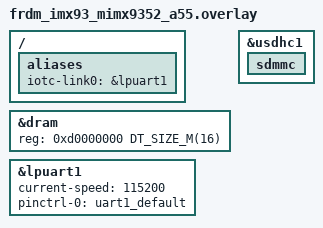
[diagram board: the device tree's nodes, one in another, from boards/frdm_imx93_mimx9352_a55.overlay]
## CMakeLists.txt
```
# gateway demo: IOTCONNECT gateway + eMMC store-and-forward on FRDM-i.MX93.
# Needs the iotc-zephyr-sdk module (-DZEPHYR_EXTRA_MODULES=<path>/iotc-zephyr-sdk).
cmake_minimum_required(VERSION 3.20.0)
find_package(Zephyr REQUIRED HINTS $ENV{ZEPHYR_BASE})
project(iotc_demo_gateway)

target_sources(app PRIVATE
  src/main.c
  src/uart_ingest.c
  src/spool.c
)

include(${CMAKE_CURRENT_SOURCE_DIR}/../../common/cmake/iotc_sdk_samples.cmake)

# quickstart_credentials.h: PUBLIC CA roots only (no device key). The
# per-device key/cert is provisioned on-chip (iotcprov provision).
target_include_directories(app PRIVATE
  ${IOTC_SDK_SAMPLES_DIR}/quickstart/src)
```

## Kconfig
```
# IOTCONNECT gateway demo configuration.

mainmenu "IOTCONNECT gateway demo"

menu "Gateway demo"

config GATEWAY_SPOOL_DISK_NAME
	string "Disk name for the store-and-forward spool"
	default "SD2"
	help
	  Zephyr disk-access name of the raw block device holding the spool
	  ring (on the FRDM-i.MX93, "SD2" = the on-SOM eMMC on uSDHC1, the
	  same disk the SDK's identity store uses).

config GATEWAY_SPOOL_SECTOR
	int "First sector of the spool ring"
	default 20100000
	help
	  Keep clear of the identity region (default sector 20,000,000 + 16)
	  and of anything else on the disk. The default sits ~10 GB into the
	  16 GB eMMC user area, which the SD-booted demo does not otherwise
	  use.

config GATEWAY_SPOOL_SLOTS
	int "Spool capacity in records (3 sectors / 1536 B each)"
	default 2048
	help
	  2048 slots = 3 MB = several hours of offline buffering at the demo
	  cadence (one gateway record per interval + one record per child
	  message).

config GATEWAY_SELF_TAG
	string "Gateway's own tag in the gateway template"
	default "gw"
	help
	  The "tg" stamped on the gateway's own telemetry records. Gateway
	  templates scope attributes by tag, and the platform binds values
	  only when the record's tg matches the attribute's tag.

config GATEWAY_LINK0_CHILD_ID
	string "Child device unique id for UART link 0"
	default "frdmmcxe31b01"
	help
	  Must match the child device's Unique ID on the platform. The
	  uart-telemetry-source demo announces itself as "<board>-01".

config GATEWAY_LINK0_TAG
	string "Gateway-template tag for UART link 0's child"
	default "uartsrc"
	help
	  The "tg" value sent with this child's records; must match the tag
	  the child template is attached under in the GATEWAY template.
	  Leave empty to omit "tg".

config GATEWAY_LINK1_CHILD_ID
	string "Child device unique id for UART link 1"
	default "frdmmcxw7201"

config GATEWAY_LINK1_TAG
	string "Gateway-template tag for UART link 1's child"
	default "uartsrc"

endmenu

source "Kconfig.zephyr"
```

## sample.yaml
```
sample:
  name: IOTCONNECT gateway demo
  description: >
    IOTCONNECT gateway with offline store-and-forward on the FRDM-i.MX93
    (Cortex-A55, Zephyr): ingests IOTCONNECT 2.1 JSON lines from
    connectivity-less MCUs over UART (demos/uart-telemetry-source), forwards
    them as child-device records over one MQTT/TLS uplink, and spools every
    record to a raw eMMC ring while offline -- reconnect backfills the
    timeline. Built on the iotc-zephyr-sdk.
tests:
  sample.iotconnect.gateway:
    harness: net
    platform_allow:
      - frdm_imx93/mimx9352/a55
    tags:
      - iotconnect
      - net
      - gateway
```

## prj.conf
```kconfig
# IOTCONNECT gateway demo -- vendor-neutral baseline.
# Provisioning model = quickstart (identity provisioned at runtime, on-chip
# keygen, only public CA roots compiled in). Board-specific networking,
# storage backend, and UART links live in boards/<board>.conf/.overlay.

# --- SDK + cloud -------------------------------------------------------------
CONFIG_IOTCONNECT=y
CONFIG_IOTCONNECT_DRA=y
CONFIG_IOTCONNECT_CT_AWS=y
CONFIG_IOTCONNECT_DRA_DISCOVERY_HOST="awsdiscovery.iotconnect.io"

# --- On-device provisioning (shell commands; storage backend per board) ------
# IDENTITY_NVS is the umbrella identity-store option; the backend (NVS vs
# TF-M PS vs raw disk) is picked by the board conf.
CONFIG_IOTCONNECT_IDENTITY_NVS=y
CONFIG_IOTCONNECT_ONDEVICE_KEYGEN=y
CONFIG_IOTCONNECT_SHELL=y
CONFIG_MBEDTLS_USER_CONFIG_FILE="iotc_mbedtls_config.h"
CONFIG_PSA_WANT_ALG_ECDSA=y
CONFIG_PSA_WANT_KEY_TYPE_ECC_KEY_PAIR_GENERATE=y
CONFIG_PSA_WANT_KEY_TYPE_ECC_KEY_PAIR_EXPORT=y
CONFIG_PSA_WANT_ECC_SECP_R1_256=y

# --- Shell (base64 cert/key + JSON paste need generous buffers) --------------
CONFIG_SHELL=y
CONFIG_SHELL_CMD_BUFF_SIZE=3072
CONFIG_SHELL_BACKEND_SERIAL_RX_RING_BUFFER_SIZE=4096
CONFIG_KERNEL_SHELL=y
CONFIG_REBOOT=y

# --- UART ingest links (interrupt-driven RX) ---------------------------------
CONFIG_SERIAL=y
CONFIG_UART_INTERRUPT_DRIVEN=y
CONFIG_RING_BUFFER=y

# --- Spool record integrity --------------------------------------------------
CONFIG_CRC=y

# --- Networking (native Zephyr IP stack) -------------------------------------
CONFIG_NETWORKING=y
CONFIG_NET_NATIVE=y
CONFIG_NET_IPV4=y
CONFIG_NET_IPV6=n
CONFIG_NET_TCP=y
CONFIG_NET_UDP=y
CONFIG_NET_SOCKETS=y
CONFIG_NET_SOCKETS_SOCKOPT_TLS=y
CONFIG_NET_SOCKETS_TLS_MAX_CONTEXTS=4
CONFIG_DNS_RESOLVER=y
CONFIG_NET_CONNECTION_MANAGER=y
CONFIG_NET_MGMT=y
CONFIG_NET_MGMT_EVENT=y
CONFIG_POSIX_API=y

# --- TLS / mbedTLS -----------------------------------------------------------
CONFIG_TLS_CREDENTIALS=y
CONFIG_MBEDTLS=y
CONFIG_MBEDTLS_ENABLE_HEAP=y
CONFIG_MBEDTLS_HEAP_SIZE=75000
CONFIG_MBEDTLS_SSL_MAX_CONTENT_LEN=16384
CONFIG_MBEDTLS_PEM_PARSE_C=y
CONFIG_MBEDTLS_SSL_SERVER_NAME_INDICATION=y
CONFIG_MBEDTLS_CIPHERSUITE_TLS_ECDHE_RSA_WITH_AES_128_GCM_SHA256=y
# discovery.iotconnect.io (production instances) only accepts TLS 1.2 CBC suites
CONFIG_MBEDTLS_CIPHERSUITE_TLS_ECDHE_RSA_WITH_AES_128_CBC_SHA256=y
CONFIG_MBEDTLS_CIPHERSUITE_TLS_ECDHE_ECDSA_WITH_AES_128_GCM_SHA256=y
CONFIG_ENTROPY_GENERATOR=y

# --- MQTT / HTTP / SNTP ------------------------------------------------------
CONFIG_MQTT_LIB=y
CONFIG_MQTT_LIB_TLS=y
CONFIG_MQTT_KEEPALIVE=30
CONFIG_HTTP_CLIENT=y
CONFIG_SNTP=y
CONFIG_POSIX_TIMERS=y

# Child records + gateway vitals in one 2.1 message need TX headroom.
CONFIG_IOTCONNECT_MQTT_TX_BUF_SIZE=2048

# --- libc / heap / stacks ----------------------------------------------------
CONFIG_PICOLIBC_IO_FLOAT=y
CONFIG_MAIN_STACK_SIZE=12288
CONFIG_SHELL_STACK_SIZE=8192
CONFIG_HEAP_MEM_POOL_SIZE=65536
CONFIG_IOTCONNECT_THREAD_STACK_SIZE=6144

# --- Logging -----------------------------------------------------------------
CONFIG_LOG=y
CONFIG_IOTCONNECT_LOG_LEVEL_INF=y

# Device vitals: append a "sys" object (CPU/heap/temp/uptime/reset) to telemetry.
CONFIG_IOTCONNECT_DEVICE_VITALS=y
```

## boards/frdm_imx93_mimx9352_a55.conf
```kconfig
# FRDM-IMX93 Cortex-A55 board config for the gateway demo.
#
# Same Zephyr-on-A55 platform recipe as the quickstart (Ethernet bearer,
# raw-eMMC identity store -- this target has no NOR flash and no NVS), plus
# the demo's own eMMC spool region and the lpuart1 ingest link enabled in
# boards/frdm_imx93_mimx9352_a55.overlay.
#
# Board target: frdm_imx93/mimx9352/a55  (needs the aarch64-zephyr-elf
# toolchain; build with USE_NXP_SPSDK_IMAGE=y for the bootable flash.bin).

# --- Bearer: native Ethernet (i.MX93 ENET, RGMII, Motorcomm YT8521 PHY) -----
CONFIG_NET_L2_ETHERNET=y
CONFIG_ETH_NXP_ENET=y
CONFIG_MDIO=y
CONFIG_NET_DHCPV4=y
CONFIG_NET_CONFIG_AUTO_INIT=y
CONFIG_NET_CONFIG_NEED_IPV4=y
CONFIG_NET_CONFIG_SETTINGS=y
CONFIG_NET_PKT_RX_COUNT=16
CONFIG_NET_PKT_TX_COUNT=16
CONFIG_NET_BUF_RX_COUNT=32
CONFIG_NET_BUF_TX_COUNT=32
CONFIG_NET_CONTEXT_RCVTIMEO=y
CONFIG_MBEDTLS_HEAP_SIZE=60000

# --- Identity persistence: raw eMMC sector region (no NOR flash here) --------
CONFIG_SETTINGS=n
CONFIG_SETTINGS_NVS=n
CONFIG_NVS=n
CONFIG_FLASH=n
CONFIG_FLASH_MAP=n
CONFIG_IOTCONNECT_IDENTITY_DISK=y
CONFIG_IOTCONNECT_IDENTITY_DISK_NAME="SD2"
CONFIG_IOTCONNECT_IDENTITY_DISK_SECTOR=20000000

# --- eMMC block access: identity store + the demo's spool ring ---------------
# (spool region: CONFIG_GATEWAY_SPOOL_* defaults -- sector 20,100,000, 3 MB)
CONFIG_DISK_ACCESS=y
CONFIG_DISK_DRIVER_MMC=y
CONFIG_MMC_STACK=y
CONFIG_SDHC=y
```

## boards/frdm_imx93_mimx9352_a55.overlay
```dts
/*
 * FRDM-IMX93 Cortex-A55 gateway overlay.
 *   - Extend the Zephyr DRAM window (the 1 MB board default is too small for
 *     arm64 + net + TLS + keygen). Must fit the DDR region your BSP reserves.
 *   - Enable usdhc1 (the on-SOM eMMC, disk "SD2"): the SDK's identity store
 *     and the demo's store-and-forward spool ring both live there. The ROM
 *     boots from the uSDHC2 SD slot; per the board doc Zephyr storage must
 *     use a DIFFERENT controller, and the eMMC qualifies.
 *   - Enable lpuart1 as UART ingest link 0 (alias iotc-link0): wire a
 *     uart-telemetry-source board's TX to UART1 RXD = 40-pin header P11
 *     pin 7 (net GPIO_IO04; GND on pin 9), 115200 8N1. lpuart2 stays the
 *     console/shell. UART1 doubles as the A55 debug port through the
 *     CH342F bridge, so the second debug COM port can emulate a source
 *     (tools/emulate_source.py) -- but not while a real TX is wired.
 */

/ {
	aliases {
		iotc-link0 = &lpuart1;
	};
};

&dram {
	reg = <0xd0000000 DT_SIZE_M(16)>;
};

&usdhc1 {
	status = "okay";

	sdmmc {
		status = "okay";
	};
};

&lpuart1 {
	status = "okay";
	current-speed = <115200>;
	pinctrl-0 = <&uart1_default>;
	pinctrl-names = "default";
};
```

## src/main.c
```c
/*
 * Copyright (c) 2026 Avnet, Inc.
 * SPDX-License-Identifier: MIT
 *
 * gateway demo -- an IOTCONNECT gateway with offline store-and-forward, on
 * the NXP FRDM-i.MX93 (Cortex-A55) running Zephyr.
 *
 * Completes the repo's "telemetry source" arc: connectivity-less MCUs running
 * demos/uart-telemetry-source (FRDM-MCXE31B, FRDM-MCXW72) print IOTCONNECT
 * 2.1 JSON lines on a UART; this gateway ingests those lines, wraps each one
 * as a CHILD-DEVICE record ("id" + "tg" per the 2.1 gateway schema), adds its
 * own gateway telemetry + vitals, and publishes everything over one MQTT/TLS
 * connection.
 *
 * Resilience is the headline: when the uplink drops (pull the Ethernet
 * cable), every record -- gateway and children -- is spooled to a raw-sector
 * ring on the on-SOM eMMC with its original timestamp embedded. On reconnect
 * the spool drains oldest-first and the platform backfills the timeline.
 * Nothing is lost; the dashboard shows a gap-free history plus honest
 * spool/drop counters.
 *
 * Cloud commands: interval <s>, spool-info, spool-wipe, links, reboot.
 *
 * Child devices are created on the platform under this gateway device; each
 * UART link maps to one child (unique id + template tag) via Kconfig:
 *   CONFIG_GATEWAY_LINK0_CHILD_ID / CONFIG_GATEWAY_LINK0_TAG   (and LINK1).
 */

#include <stdbool.h>
#include <stddef.h>
#include <stdint.h>
#include <stdio.h>
#include <stdlib.h>
#include <string.h>
#include <ctype.h>

#include <zephyr/kernel.h>
#include <zephyr/logging/log.h>
#include <zephyr/sys/printk.h>
#include <zephyr/sys/reboot.h>
#include <zephyr/net/net_if.h>
#include <zephyr/net/net_mgmt.h>
#include <zephyr/net/net_event.h>
#include <zephyr/net/conn_mgr_monitor.h>

#include <cJSON.h>

#include "iotconnect.h"
#include "iotcl.h"
#include "iotcl_telemetry.h"
#include "iotcl_util.h"
#include "iotcl_c2d.h"
#include "iotc_time.h"
#include "iotc_mqtt_client.h"      /* raw publish for child/spooled records */
#include "iotconnect_identity.h"
#if defined(CONFIG_IOTCONNECT_DEVICE_VITALS)
#include "iotconnect_vitals.h"
#endif
#include "quickstart_credentials.h" /* PUBLIC CA roots only (no device key) */

#include "uart_ingest.h"
#include "spool.h"

LOG_MODULE_REGISTER(gateway, LOG_LEVEL_INF);

#define RECONNECT_PERIOD_SEC 20
#define DRAIN_PER_TICK 4
#define ISO_TS_LEN 32

static volatile int publish_interval_sec = 10;
static bool spool_ok;
static uint32_t fwd_total;          /* child records forwarded (live) */

static const struct {
	const char *child_id;
	const char *tag;
} link_map[INGEST_MAX_LINKS] = {
	{ CONFIG_GATEWAY_LINK0_CHILD_ID, CONFIG_GATEWAY_LINK0_TAG },
	{ CONFIG_GATEWAY_LINK1_CHILD_ID, CONFIG_GATEWAY_LINK1_TAG },
};

static void print_guide(const char *reason)
{
	printk("\n");
	printk("========================================================\n");
	printk("  IOTCONNECT GATEWAY -- device is not provisioned\n");
	printk("  (%s)\n", reason);
	printk("--------------------------------------------------------\n");
	printk("  1) Generate this device's identity ON the device:\n");
	printk("        iotcprov provision <your-duid>\n");
	printk("  2) In IOTCONNECT: import the gateway template, Create\n");
	printk("     Device (Self-Signed, GATEWAY) on it, and paste the\n");
	printk("     certificate printed above. Create the child devices\n");
	printk("     under it (see README).\n");
	printk("  3) Paste the downloaded iotcDeviceConfig.json:\n");
	printk("        iotc config\n");
	printk("        { ...paste the json block... }\n");
	printk("  4) Connect:  kernel reboot cold\n");
	printk("========================================================\n\n");
}

/* --- Publishing ------------------------------------------------------------ */

static void publish_raw(const char *json)
{
	IotclMqttConfig *mc = iotcl_mqtt_get_config();

	if (mc != NULL && mc->pub_rpt != NULL) {
		iotc_mqtt_client_publish(mc->pub_rpt, json);
	}
}

/*
 * Derive the platform child Unique ID from the source's self-reported board
 * name: strip separators (the platform allows only alphanumerics in child
 * IDs) and append "01", mirroring the source's "<board>-01" duid convention.
 * "frdm_mcxe31b" -> "frdmmcxe31b01". This makes the single wired link
 * board-agnostic: whichever source MCU is plugged in shows up as itself.
 */
static void child_id_from_board(const char *board, char *out, size_t out_size)
{
	size_t o = 0;

	for (; *board != '\0' && o < out_size - 3; board++) {
		char c = *board;

		if ((c >= 'a' && c <= 'z') || (c >= 'A' && c <= 'Z') ||
		    (c >= '0' && c <= '9')) {
			out[o++] = c;
		}
	}
	out[o++] = '0';
	out[o++] = '1';
	out[o] = '\0';
}

/*
 * Wrap one source line (a 2.1 message from uart-telemetry-source, shape
 * {"d":[{"d":{...}}]}, or any bare JSON object) as a gateway CHILD record:
 *   {"d":[{"id":"<child>","tg":"<tag>","dt":"<iso>","d":{...}}]}
 * The child id comes from the record's own "board" field when present
 * (see child_id_from_board), else the link's Kconfig default.
 * Returns a malloc'd string (cJSON_free() it) or NULL on parse failure.
 */
static char *build_child_record(int link, const char *src_json)
{
	cJSON *src = cJSON_Parse(src_json);
	cJSON *data = NULL;
	char *out = NULL;

	if (src == NULL) {
		return NULL;
	}

	/* Locate the inner data object; tolerate both envelope and bare form. */
	if (cJSON_IsObject(src)) {
		cJSON *arr = cJSON_GetObjectItem(src, "d");

		if (cJSON_IsArray(arr) && cJSON_GetArraySize(arr) > 0) {
			cJSON *item0 = cJSON_GetArrayItem(arr, 0);
			cJSON *inner = cJSON_GetObjectItem(item0, "d");

			if (cJSON_IsObject(inner)) {
				data = cJSON_DetachItemFromObject(item0, "d");
			}
		} else if (arr == NULL) {
			data = src; /* bare object: use it wholesale */
			src = NULL;
		}
	}
	if (data == NULL) {
		cJSON_Delete(src);
		return NULL;
	}

	cJSON *root = cJSON_CreateObject();
	cJSON *darr = cJSON_AddArrayToObject(root, "d");
	cJSON *item = cJSON_CreateObject();
	char ts[ISO_TS_LEN];
	char derived_id[48];
	const char *child_id = link_map[link].child_id;
	const char *board = cJSON_GetStringValue(
		cJSON_GetObjectItem(data, "board"));

	if (board != NULL && board[0] != '\0') {
		child_id_from_board(board, derived_id, sizeof(derived_id));
		child_id = derived_id;
	}
	cJSON_AddStringToObject(item, "id", child_id);
	if (link_map[link].tag[0] != '\0') {
		cJSON_AddStringToObject(item, "tg", link_map[link].tag);
	}
	if (iotcl_iso_timestamp_now(ts, sizeof(ts)) == 0) {
		cJSON_AddStringToObject(item, "dt", ts);
	}
	cJSON_AddItemToObject(item, "d", data);
	cJSON_AddItemToArray(darr, item);

	out = cJSON_PrintUnformatted(root);
	cJSON_Delete(root);
	cJSON_Delete(src);
	return out;
}

/* Gateway-own record: link health, spool state, vitals. Publishes live when
 * connected, otherwise serializes and spools with its timestamp. */
static void publish_or_spool_gateway(bool connected)
{
	struct spool_stats sp;
	struct ingest_stats st;
	char key[24];

	spool_get_stats(&sp);

	IotclMessageHandle msg = iotcl_telemetry_create();

	if (msg == NULL) {
		return;
	}
	iotcl_telemetry_set_number(msg, "gw.online", connected ? 1 : 0);
	iotcl_telemetry_set_number(msg, "gw.links", uart_ingest_link_count());
	iotcl_telemetry_set_number(msg, "gw.fwd_total", (double)fwd_total);
	/* iotc-c-lib telemetry paths allow at most ONE dot (hardware-observed
	 * rejection of deeper nesting), so spool/link fields are flattened. */
	iotcl_telemetry_set_number(msg, "gw.spool_count", (double)sp.count);
	iotcl_telemetry_set_number(msg, "gw.spool_pushed", (double)sp.pushed);
	iotcl_telemetry_set_number(msg, "gw.spool_drained", (double)sp.drained);
	iotcl_telemetry_set_number(msg, "gw.spool_drops", (double)sp.drops);

	for (int i = 0; i < INGEST_MAX_LINKS; i++) {
		uart_ingest_get_stats(i, &st);
		if (st.lines_ok == 0 && st.lines_dropped == 0) {
			continue;
		}
		snprintf(key, sizeof(key), "gw.link%d_rx", i);
		iotcl_telemetry_set_number(msg, key, (double)st.lines_ok);
		snprintf(key, sizeof(key), "gw.link%d_drop", i);
		iotcl_telemetry_set_number(msg, key, (double)st.lines_dropped);
		snprintf(key, sizeof(key), "gw.link%d_age_s", i);
		iotcl_telemetry_set_number(msg, key, st.last_seen_ms > 0 ?
			(double)(k_uptime_get() - st.last_seen_ms) / 1000.0 : -1.0);
	}
#if defined(CONFIG_IOTCONNECT_DEVICE_VITALS)
	iotc_vitals_append(msg);
#endif

	/*
	 * Gateway-template attributes are TAG-scoped; the platform binds a
	 * record's values only when the record carries the matching "tg"
	 * (hardware-observed: tg-less gateway records display all-null).
	 * iotcl has no tg support, so serialize, inject tg into the record,
	 * and publish/spool the raw JSON.
	 */
	char *json = iotcl_telemetry_create_serialized_string(msg, false);

	iotcl_telemetry_destroy(msg);
	if (json == NULL) {
		return;
	}

	cJSON *root = cJSON_Parse(json);

	iotcl_telemetry_destroy_serialized_string(json);
	if (root == NULL) {
		return;
	}

	cJSON *item0 = cJSON_GetArrayItem(cJSON_GetObjectItem(root, "d"), 0);

	if (item0 != NULL) {
		cJSON_AddStringToObject(item0, "tg", CONFIG_GATEWAY_SELF_TAG);
	}

	char *out = cJSON_PrintUnformatted(root);

	cJSON_Delete(root);
	if (out == NULL) {
		return;
	}
	if (connected) {
		publish_raw(out);
	} else if (spool_ok) {
		(void)spool_push(out);
	}
	cJSON_free(out);
}

/* --- C2D commands ----------------------------------------------------------- */

static bool tok_is(const char *tok, size_t len, const char *name)
{
	if (strlen(name) != len) {
		return false;
	}
	for (size_t i = 0; i < len; i++) {
		if (tolower((unsigned char)tok[i]) != (unsigned char)name[i]) {
			return false;
		}
	}
	return true;
}

static void on_command(IotclC2dEventData data)
{
	const char *cmd = iotcl_c2d_get_command(data);
	const char *ack = iotcl_c2d_get_ack_id(data);
	int status = IOTCL_C2D_EVT_CMD_FAILED;
	char note[128] = "unknown command";

	LOG_INF("C2D command: %.64s", cmd ? cmd : "(null)");
	if (cmd == NULL) {
		goto out;
	}
	while (*cmd == ' ') {
		cmd++;
	}
	const char *sp = strchr(cmd, ' ');
	size_t name_len = (sp != NULL) ? (size_t)(sp - cmd) : strlen(cmd);
	const char *arg = (sp != NULL) ? sp + 1 : NULL;

	while (arg != NULL && *arg == ' ') {
		arg++;
	}
	if (arg != NULL && *arg == '\0') {
		arg = NULL;
	}

	if (tok_is(cmd, name_len, "interval") && arg != NULL) {
		int v = atoi(arg);

		if (v >= 1 && v <= 3600) {
			publish_interval_sec = v;
			status = IOTCL_C2D_EVT_CMD_SUCCESS_WITH_ACK;
			snprintf(note, sizeof(note), "interval=%ds", v);
		} else {
			snprintf(note, sizeof(note), "interval out of range");
		}
	} else if (tok_is(cmd, name_len, "spool-info")) {
		struct spool_stats sp;

		spool_get_stats(&sp);
		snprintf(note, sizeof(note),
			 "%u/%u queued, pushed=%u drained=%u drops=%u%s",
			 (unsigned int)sp.count, (unsigned int)sp.capacity,
			 (unsigned int)sp.pushed, (unsigned int)sp.drained,
			 (unsigned int)sp.drops,
			 spool_ok ? "" : " (SPOOL OFFLINE)");
		status = IOTCL_C2D_EVT_CMD_SUCCESS_WITH_ACK;
	} else if (tok_is(cmd, name_len, "spool-wipe")) {
		if (spool_wipe() == 0) {
			status = IOTCL_C2D_EVT_CMD_SUCCESS_WITH_ACK;
			snprintf(note, sizeof(note), "spool wiped");
		} else {
			snprintf(note, sizeof(note), "spool wipe failed");
		}
	} else if (tok_is(cmd, name_len, "links")) {
		struct ingest_stats s0, s1;

		uart_ingest_get_stats(0, &s0);
		uart_ingest_get_stats(1, &s1);
		snprintf(note, sizeof(note),
			 "link0(%s->%s): rx=%u drop=%u | link1(%s->%s): rx=%u drop=%u",
			 uart_ingest_link_name(0), link_map[0].child_id,
			 (unsigned int)s0.lines_ok, (unsigned int)s0.lines_dropped,
			 uart_ingest_link_name(1), link_map[1].child_id,
			 (unsigned int)s1.lines_ok, (unsigned int)s1.lines_dropped);
		status = IOTCL_C2D_EVT_CMD_SUCCESS_WITH_ACK;
	} else if (tok_is(cmd, name_len, "reboot")) {
		if (ack != NULL) {
			(void)iotcl_mqtt_send_cmd_ack(
				ack, IOTCL_C2D_EVT_CMD_SUCCESS_WITH_ACK, NULL);
		}
		k_sleep(K_MSEC(500));
		sys_reboot(SYS_REBOOT_COLD);
	}

out:
	if (ack != NULL) {
		(void)iotcl_mqtt_send_cmd_ack(ack, status, note);
	}
}

static void on_connection_status(IotConnectMqttStatus status)
{
	LOG_INF("MQTT status: %d", (int)status);
}

/* --- Network bring-up ------------------------------------------------------- */

static K_SEM_DEFINE(l4_connected_sem, 0, 1);
static struct net_mgmt_event_callback l4_cb;
#define L4_EVENT_MASK (NET_EVENT_L4_CONNECTED | NET_EVENT_L4_DISCONNECTED)

static void l4_event_handler(struct net_mgmt_event_callback *cb,
			     uint64_t mgmt_event, struct net_if *iface)
{
	ARG_UNUSED(cb);
	ARG_UNUSED(iface);
	if (mgmt_event == NET_EVENT_L4_CONNECTED) {
		LOG_INF("Network connectivity established (L4 up)");
		k_sem_give(&l4_connected_sem);
	} else if (mgmt_event == NET_EVENT_L4_DISCONNECTED) {
		LOG_WRN("Network connectivity lost (L4 down) -- spooling");
	}
}

static int network_up(void)
{
	struct net_if *iface = net_if_get_default();

	if (iface == NULL) {
		LOG_ERR("No default network interface");
		return -ENODEV;
	}
	net_mgmt_init_event_callback(&l4_cb, l4_event_handler, L4_EVENT_MASK);
	net_mgmt_add_event_callback(&l4_cb);
	if (!net_if_is_up(iface)) {
		int ret = net_if_up(iface);

		if (ret && ret != -EALREADY) {
			LOG_ERR("net_if_up failed (%d)", ret);
			return ret;
		}
	}
	conn_mgr_mon_resend_status();
	LOG_INF("Waiting for network connectivity...");
	k_sem_take(&l4_connected_sem, K_FOREVER);
	return 0;
}

/* --- Main ------------------------------------------------------------------- */

static char line_buf[INGEST_LINE_MAX];
static char spool_out[SPOOL_PAYLOAD_MAX + 1];

/* Drain queued source lines from every link; forward live or spool. */
static void ingest_children(bool connected)
{
	for (int link = 0; link < INGEST_MAX_LINKS; link++) {
		int n;

		while ((n = uart_ingest_pop(link, line_buf,
					    sizeof(line_buf))) > 0) {
			char *rec = build_child_record(link, line_buf);

			if (rec == NULL) {
				LOG_WRN("link%d: unparseable line dropped", link);
				continue;
			}
			if (connected) {
				publish_raw(rec);
				fwd_total++;
			} else if (spool_ok) {
				(void)spool_push(rec);
			}
			cJSON_free(rec);
		}
	}
}

int main(void)
{
	int ret;

	LOG_INF("gateway demo starting (%d UART link(s) in devicetree)",
		uart_ingest_link_count());

	if (uart_ingest_init() != 0) {
		LOG_ERR("UART ingest init failed");
		return 0;
	}
	spool_ok = spool_init() == 0;
	if (!spool_ok) {
		LOG_WRN("eMMC spool unavailable -- offline records will be LOST");
	}

	struct iotc_identity id;

	if (iotc_identity_load(&id) != 0) {
		print_guide("no identity stored");
		return 0; /* stay alive at the shell for provisioning */
	}
	LOG_INF("Provisioned as duid=%s -- bringing up network", id.duid);

	ret = network_up();
	if (ret) {
		return 0;
	}
	ret = iotc_time_sync(CONFIG_IOTCONNECT_SNTP_SERVER,
			     CONFIG_IOTCONNECT_SNTP_TIMEOUT_MS);
	if (ret) {
		LOG_ERR("SNTP sync failed (%d); TLS will likely fail", ret);
		return 0;
	}

	IotConnectClientConfig config;

	iotconnect_sdk_init_config(&config);
#if defined(CONFIG_IOTCONNECT_CT_AWS)
	config.connection_type = IOTC_CT_AWS;
#elif defined(CONFIG_IOTCONNECT_CT_AZURE)
	config.connection_type = IOTC_CT_AZURE;
#endif
	config.cpid = (char *)id.cpid;
	config.env = (char *)id.env;
	config.duid = (char *)id.duid;

	config.auth_info.type = IOTC_AT_X509;
	config.auth_info.ca_cert = broker_ca_pem;
	config.auth_info.ca_cert_len = sizeof(broker_ca_pem);
	config.auth_info.dra_ca = dra_ca_pem;
	config.auth_info.dra_ca_len = sizeof(dra_ca_pem);
	config.auth_info.data.cert_info.device_cert = id.device_cert;
	config.auth_info.data.cert_info.device_cert_len = id.device_cert_len;
	config.auth_info.data.cert_info.device_key = id.device_key;
	config.auth_info.data.cert_info.device_key_len = id.device_key_len;

	config.status_cb = on_connection_status;
	config.cmd_cb = on_command;
	config.verbose = true;

	ret = iotconnect_sdk_init(&config);
	if (ret) {
		LOG_ERR("iotconnect_sdk_init failed (%d)", ret);
		return 0;
	}

	/*
	 * Resilient main loop: unlike the point-demos, a lost connection does
	 * NOT pause the work -- ingest and the periodic gateway record keep
	 * running, records divert to the eMMC spool, and reconnects are
	 * attempted in the background of the same loop.
	 */
	bool was_connected = false;
	int64_t last_pub = 0, last_reconnect = 0;

	while (true) {
		int64_t now = k_uptime_get();
		bool connected = iotconnect_sdk_is_connected();

		if (!connected &&
		    (last_reconnect == 0 ||
		     now - last_reconnect >= RECONNECT_PERIOD_SEC * 1000)) {
			if (was_connected) {
				iotconnect_sdk_disconnect();
				was_connected = false;
			}
			last_reconnect = now;
			LOG_INF("connecting...");
			if (iotconnect_sdk_connect() == 0) {
				connected = true;
				LOG_INF("Connected. Try: links, spool-info; "
					"then pull the cable.");
			} else {
				struct spool_stats sptmp;

				spool_get_stats(&sptmp);
				LOG_WRN("connect failed; %u records spooled so far",
					(unsigned int)sptmp.count);
			}
		}
		if (connected) {
			was_connected = true;
		}

		ingest_children(connected);

		if (last_pub == 0 ||
		    now - last_pub >= (int64_t)publish_interval_sec * 1000) {
			publish_or_spool_gateway(connected);
			last_pub = now;
		}

		if (connected && spool_ok) {
			for (int i = 0; i < DRAIN_PER_TICK; i++) {
				int n = spool_peek(spool_out, sizeof(spool_out));

				if (n <= 0) {
					break;
				}
				publish_raw(spool_out);
				(void)spool_commit();
			}
		}

		k_sleep(K_MSEC(500));
	}
	return 0;
}
```

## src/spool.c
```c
/*
 * Copyright (c) 2026 Avnet, Inc.
 * SPDX-License-Identifier: MIT
 */
#include <string.h>

#include <zephyr/kernel.h>
#include <zephyr/logging/log.h>
#include <zephyr/storage/disk_access.h>
#include <zephyr/sys/crc.h>

#include "spool.h"

LOG_MODULE_REGISTER(spool, LOG_LEVEL_INF);

#define SPOOL_DISK    CONFIG_GATEWAY_SPOOL_DISK_NAME
#define BASE_SECTOR   CONFIG_GATEWAY_SPOOL_SECTOR
#define NSLOTS        CONFIG_GATEWAY_SPOOL_SLOTS
#define SLOT_BYTES    (SPOOL_SLOT_SECTORS * 512)

#define REC_MAGIC 0x52544F49u /* "IOTR" little-endian */

struct rec_hdr {
	uint32_t magic;
	uint32_t seq;
	uint16_t len;
	uint16_t rsvd;
	uint32_t crc;      /* CRC32 over the payload bytes */
} __packed;

BUILD_ASSERT(sizeof(struct rec_hdr) == 16, "spool record header is 16 B");

static K_MUTEX_DEFINE(spool_mutex);
static uint8_t slot_buf[SLOT_BYTES];  /* shared read/write staging */
static uint32_t head_seq;             /* oldest queued record */
static uint32_t tail_seq;             /* next sequence to write */
static uint32_t rec_count;
static struct spool_stats stats;
static bool ready;

static uint32_t slot_of(uint32_t seq)
{
	return BASE_SECTOR + (seq % NSLOTS) * SPOOL_SLOT_SECTORS;
}

static int read_hdr(uint32_t slot_sector, struct rec_hdr *h)
{
	/* Header lives in the slot's first sector. */
	int ret = disk_access_read(SPOOL_DISK, slot_buf, slot_sector, 1);

	if (ret == 0) {
		memcpy(h, slot_buf, sizeof(*h));
	}
	return ret;
}

int spool_init(void)
{
	uint32_t max_seq = 0, min_seq = UINT32_MAX;
	uint32_t valid = 0;
	int ret;

	ret = disk_access_init(SPOOL_DISK);
	if (ret != 0) {
		LOG_ERR("disk %s init failed (%d); spooling disabled",
			SPOOL_DISK, ret);
		return ret;
	}

	/* Recover the ring: valid slots carry the magic; the live window is
	 * the contiguous sequence range still resident in the ring. */
	for (uint32_t i = 0; i < NSLOTS; i++) {
		struct rec_hdr h;

		if (read_hdr(BASE_SECTOR + i * SPOOL_SLOT_SECTORS, &h) != 0) {
			return -EIO;
		}
		if (h.magic != REC_MAGIC || h.len > SPOOL_PAYLOAD_MAX) {
			continue;
		}
		valid++;
		max_seq = MAX(max_seq, h.seq);
		min_seq = MIN(min_seq, h.seq);
	}

	if (valid == 0) {
		head_seq = tail_seq = 0;
		rec_count = 0;
	} else {
		/* Stale slots from older overwritten laps sit below the live
		 * window; clamp to the newest NSLOTS-sized window. */
		tail_seq = max_seq + 1;
		head_seq = MAX(min_seq, (max_seq >= NSLOTS - 1) ?
					 max_seq - (NSLOTS - 1) : 0);
		rec_count = tail_seq - head_seq;
	}
	stats.capacity = NSLOTS;
	stats.count = rec_count;
	ready = true;
	LOG_INF("spool: %u slots @ sector %u, %u queued (seq %u..%u)",
		(unsigned int)NSLOTS, (unsigned int)BASE_SECTOR,
		(unsigned int)rec_count, (unsigned int)head_seq,
		(unsigned int)tail_seq);
	return 0;
}

int spool_push(const char *json)
{
	size_t len = strlen(json);
	struct rec_hdr h;
	int ret;

	if (!ready) {
		return -ENODEV;
	}
	if (len > SPOOL_PAYLOAD_MAX) {
		k_mutex_lock(&spool_mutex, K_FOREVER);
		stats.drops++;
		k_mutex_unlock(&spool_mutex);
		return -EMSGSIZE;
	}

	k_mutex_lock(&spool_mutex, K_FOREVER);
	if (rec_count == NSLOTS) {
		/* Ring full: sacrifice the oldest record, keep the newest. */
		head_seq++;
		rec_count--;
		stats.drops++;
	}

	h.magic = REC_MAGIC;
	h.seq = tail_seq;
	h.len = (uint16_t)len;
	h.rsvd = 0;
	h.crc = crc32_ieee((const uint8_t *)json, len);

	memset(slot_buf, 0, SLOT_BYTES);
	memcpy(slot_buf, &h, sizeof(h));
	memcpy(slot_buf + sizeof(h), json, len);

	ret = disk_access_write(SPOOL_DISK, slot_buf, slot_of(tail_seq),
				SPOOL_SLOT_SECTORS);
	if (ret == 0) {
		/* Flush the eMMC write cache: spooled records exist precisely
		 * to survive power loss. */
		(void)disk_access_ioctl(SPOOL_DISK, DISK_IOCTL_CTRL_SYNC, NULL);
		tail_seq++;
		rec_count++;
		stats.pushed++;
		stats.count = rec_count;
	}
	k_mutex_unlock(&spool_mutex);
	return ret;
}

int spool_peek(char *buf, size_t buf_size)
{
	struct rec_hdr h;
	int ret = 0;

	if (!ready) {
		return -ENODEV;
	}
	k_mutex_lock(&spool_mutex, K_FOREVER);
	while (rec_count > 0) {
		ret = disk_access_read(SPOOL_DISK, slot_buf, slot_of(head_seq),
				       SPOOL_SLOT_SECTORS);
		if (ret != 0) {
			break;
		}
		memcpy(&h, slot_buf, sizeof(h));
		if (h.magic != REC_MAGIC || h.seq != head_seq ||
		    h.len > SPOOL_PAYLOAD_MAX || h.len >= buf_size ||
		    crc32_ieee(slot_buf + sizeof(h), h.len) != h.crc) {
			/* Corrupt/foreign slot: skip it rather than wedge. */
			LOG_WRN("spool: skipping bad record seq %u",
				(unsigned int)head_seq);
			head_seq++;
			rec_count--;
			stats.drops++;
			stats.count = rec_count;
			continue;
		}
		memcpy(buf, slot_buf + sizeof(h), h.len);
		buf[h.len] = '\0';
		ret = h.len;
		break;
	}
	k_mutex_unlock(&spool_mutex);
	return (rec_count == 0 && ret == 0) ? 0 : ret;
}

int spool_commit(void)
{
	int ret = 0;

	if (!ready) {
		return -ENODEV;
	}
	k_mutex_lock(&spool_mutex, K_FOREVER);
	if (rec_count > 0) {
		/* Invalidate the slot header so a reboot cannot re-send it. */
		memset(slot_buf, 0, 512);
		ret = disk_access_write(SPOOL_DISK, slot_buf,
					slot_of(head_seq), 1);
		head_seq++;
		rec_count--;
		stats.drained++;
		stats.count = rec_count;
	}
	k_mutex_unlock(&spool_mutex);
	return ret;
}

int spool_wipe(void)
{
	int ret = 0;

	if (!ready) {
		return -ENODEV;
	}
	k_mutex_lock(&spool_mutex, K_FOREVER);
	memset(slot_buf, 0, 512);
	for (uint32_t i = 0; i < NSLOTS && ret == 0; i++) {
		ret = disk_access_write(SPOOL_DISK, slot_buf,
					BASE_SECTOR + i * SPOOL_SLOT_SECTORS, 1);
	}
	head_seq = tail_seq = 0;
	rec_count = 0;
	stats.count = 0;
	k_mutex_unlock(&spool_mutex);
	return ret;
}

void spool_get_stats(struct spool_stats *out)
{
	k_mutex_lock(&spool_mutex, K_FOREVER);
	*out = stats;
	k_mutex_unlock(&spool_mutex);
}
```

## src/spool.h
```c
/*
 * Copyright (c) 2026 Avnet, Inc.
 * SPDX-License-Identifier: MIT
 *
 * Store-and-forward spool: a raw-sector ring queue on the on-SOM eMMC.
 *
 * The i.MX93 A55 target has no NOR flash and mounts no filesystem; the SDK
 * already persists the device identity to a raw eMMC sector region
 * (CONFIG_IOTCONNECT_IDENTITY_DISK). The spool follows the same pattern: a
 * fixed ring of 3-sector (1536 B) slots, each holding one ready-to-publish
 * telemetry JSON string with a magic/sequence/CRC32 header. No filesystem,
 * no format step, deterministic wear.
 *
 * While the gateway is offline every record (its own and each child's) is
 * pushed here with its original "dt" timestamp embedded in the JSON; on
 * reconnect the main loop drains oldest-first and the platform backfills the
 * timeline. When the ring fills, the OLDEST record is overwritten and
 * counted in drops (newest data wins). Popped slots are invalidated on
 * commit so a reboot never re-sends drained records.
 *
 * Location/size come from Kconfig (CONFIG_GATEWAY_SPOOL_*); the defaults sit
 * well above the identity region on the otherwise-unused eMMC user area.
 */
#ifndef SPOOL_H
#define SPOOL_H

#include <stddef.h>
#include <stdint.h>

#ifdef __cplusplus
extern "C" {
#endif

#define SPOOL_SLOT_SECTORS 3
#define SPOOL_PAYLOAD_MAX  (SPOOL_SLOT_SECTORS * 512 - 16 /* header */ - 1)

struct spool_stats {
	uint32_t count;     /* records currently queued */
	uint32_t capacity;  /* total slots */
	uint32_t pushed;    /* since boot */
	uint32_t drained;   /* since boot */
	uint32_t drops;     /* ring-full overwrites + oversize rejects */
};

/* Scan the ring to recover head/tail. Returns 0 or -errno (disk missing). */
int spool_init(void);

/* Queue one JSON record (NUL-terminated). Returns 0, or -EMSGSIZE/-EIO. */
int spool_push(const char *json);

/*
 * Read the oldest record into buf without removing it. Returns its length,
 * 0 when the spool is empty, or a negative errno.
 */
int spool_peek(char *buf, size_t buf_size);

/* Invalidate the record last returned by spool_peek() (after publishing). */
int spool_commit(void);

/* Erase every slot header (slow: one write per slot). Returns 0 or -errno. */
int spool_wipe(void);

void spool_get_stats(struct spool_stats *out);

#ifdef __cplusplus
}
#endif

#endif /* SPOOL_H */
```

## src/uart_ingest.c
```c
/*
 * Copyright (c) 2026 Avnet, Inc.
 * SPDX-License-Identifier: MIT
 */
#include <string.h>

#include <zephyr/kernel.h>
#include <zephyr/device.h>
#include <zephyr/drivers/uart.h>
#include <zephyr/logging/log.h>
#include <zephyr/sys/ring_buffer.h>

#include "uart_ingest.h"

LOG_MODULE_REGISTER(uart_ingest, LOG_LEVEL_INF);

#define INGEST_PREFIX "IOTC-TELEMETRY: "
#define INGEST_PREFIX_LEN (sizeof(INGEST_PREFIX) - 1)

/* Per-link queue of complete lines: [u16 len][len bytes] records. Sized to
 * absorb ~10 s of a chatty source while the main loop is busy reconnecting. */
#define LINE_RING_SIZE (16 * 1024)

struct link {
	const struct device *dev;
	/* ISR line assembly */
	char line[INGEST_LINE_MAX];
	size_t line_len;
	bool overlong;
	/* complete-line queue, ISR producer / thread consumer */
	struct ring_buf rb;
	uint8_t rb_storage[LINE_RING_SIZE];
	struct k_spinlock lock;
	struct ingest_stats stats;
};

#if DT_NODE_EXISTS(DT_ALIAS(iotc_link0))
#define LINK0_DEV DEVICE_DT_GET(DT_ALIAS(iotc_link0))
#else
#define LINK0_DEV NULL
#endif
#if DT_NODE_EXISTS(DT_ALIAS(iotc_link1))
#define LINK1_DEV DEVICE_DT_GET(DT_ALIAS(iotc_link1))
#else
#define LINK1_DEV NULL
#endif

static struct link links[INGEST_MAX_LINKS] = {
	{ .dev = LINK0_DEV },
	{ .dev = LINK1_DEV },
};

int uart_ingest_link_count(void)
{
	int n = 0;

	for (int i = 0; i < INGEST_MAX_LINKS; i++) {
		if (links[i].dev != NULL) {
			n++;
		}
	}
	return n;
}

const char *uart_ingest_link_name(int link)
{
	if (link < 0 || link >= INGEST_MAX_LINKS || links[link].dev == NULL) {
		return "none";
	}
	return links[link].dev->name;
}

/* A full line has been assembled in ISR context; queue it if it is a
 * telemetry line, count it against the stats either way. */
static void line_complete(struct link *l)
{
	if (l->overlong) {
		l->overlong = false;
		l->line_len = 0;
		l->stats.lines_dropped++;
		return;
	}
	l->line[l->line_len] = '\0';

	if (l->line_len <= INGEST_PREFIX_LEN ||
	    strncmp(l->line, INGEST_PREFIX, INGEST_PREFIX_LEN) != 0) {
		/* Boot banner / log noise from the source: ignore silently. */
		l->line_len = 0;
		return;
	}

	const char *json = l->line + INGEST_PREFIX_LEN;
	uint16_t len = (uint16_t)(l->line_len - INGEST_PREFIX_LEN);

	K_SPINLOCK(&l->lock) {
		if (ring_buf_space_get(&l->rb) < sizeof(len) + len) {
			l->stats.lines_dropped++;
		} else {
			ring_buf_put(&l->rb, (uint8_t *)&len, sizeof(len));
			ring_buf_put(&l->rb, (const uint8_t *)json, len);
			l->stats.lines_ok++;
			l->stats.last_seen_ms = k_uptime_get();
		}
	}
	l->line_len = 0;
}

static void uart_isr(const struct device *dev, void *user_data)
{
	struct link *l = user_data;
	uint8_t chunk[64];

	if (!uart_irq_update(dev)) {
		return;
	}
	while (uart_irq_rx_ready(dev)) {
		int n = uart_fifo_read(dev, chunk, sizeof(chunk));

		for (int i = 0; i < n; i++) {
			char c = (char)chunk[i];

			if (c == '\n' || c == '\r') {
				if (l->line_len > 0 || l->overlong) {
					line_complete(l);
				}
			} else if (l->line_len < INGEST_LINE_MAX - 1) {
				l->line[l->line_len++] = c;
			} else {
				l->overlong = true;
			}
		}
	}
}

int uart_ingest_init(void)
{
	for (int i = 0; i < INGEST_MAX_LINKS; i++) {
		struct link *l = &links[i];

		if (l->dev == NULL) {
			continue;
		}
		if (!device_is_ready(l->dev)) {
			LOG_ERR("link%d UART %s not ready", i, l->dev->name);
			return -ENODEV;
		}
		ring_buf_init(&l->rb, sizeof(l->rb_storage), l->rb_storage);
		uart_irq_callback_user_data_set(l->dev, uart_isr, l);
		uart_irq_rx_enable(l->dev);
		LOG_INF("link%d: listening on %s", i, l->dev->name);
	}
	return 0;
}

int uart_ingest_pop(int link, char *buf, size_t buf_size)
{
	struct link *l;
	uint16_t len = 0;
	int out = 0;

	if (link < 0 || link >= INGEST_MAX_LINKS || links[link].dev == NULL) {
		return -EINVAL;
	}
	l = &links[link];

	K_SPINLOCK(&l->lock) {
		if (ring_buf_size_get(&l->rb) < sizeof(len)) {
			out = 0;
		} else {
			ring_buf_get(&l->rb, (uint8_t *)&len, sizeof(len));
			if (len >= buf_size) {
				/* Cannot deliver; discard to stay in sync. */
				uint8_t sink[64];

				for (uint16_t r = len; r > 0;) {
					uint32_t g = ring_buf_get(&l->rb, sink,
								  MIN(r, sizeof(sink)));
					r -= (uint16_t)g;
				}
				l->stats.lines_dropped++;
				out = -EMSGSIZE;
			} else {
				ring_buf_get(&l->rb, (uint8_t *)buf, len);
				buf[len] = '\0';
				out = len;
			}
		}
	}
	return out;
}

void uart_ingest_get_stats(int link, struct ingest_stats *out)
{
	memset(out, 0, sizeof(*out));
	if (link >= 0 && link < INGEST_MAX_LINKS && links[link].dev != NULL) {
		K_SPINLOCK(&links[link].lock) {
			*out = links[link].stats;
		}
	}
}
```

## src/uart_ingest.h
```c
/*
 * Copyright (c) 2026 Avnet, Inc.
 * SPDX-License-Identifier: MIT
 *
 * UART ingest for the gateway demo: receives line-framed IOTCONNECT 2.1
 * telemetry from connectivity-less MCUs running the uart-telemetry-source
 * demo, which print one message per period as:
 *
 *   IOTC-TELEMETRY: {"d":[{"d":{...fields...}}]}\n
 *
 * Each link is a UART named by a devicetree alias (iotc-link0, iotc-link1).
 * RX runs interrupt-driven; complete "IOTC-TELEMETRY:" lines are queued in a
 * per-link ring buffer (anything else on the wire -- boot banners, logs -- is
 * discarded). The main loop pops lines at its own pace; if it stalls (e.g.
 * during a reconnect attempt) the ring absorbs the burst and the drop
 * counters record any overflow honestly.
 */
#ifndef UART_INGEST_H
#define UART_INGEST_H

#include <stdbool.h>
#include <stddef.h>
#include <stdint.h>

#ifdef __cplusplus
extern "C" {
#endif

/* Longest accepted JSON line (source messages incl. vitals are < 1 KB). */
#define INGEST_LINE_MAX 1024

#define INGEST_MAX_LINKS 2

struct ingest_stats {
	uint32_t lines_ok;      /* complete IOTC-TELEMETRY lines queued */
	uint32_t lines_dropped; /* ring full or line overlong */
	int64_t last_seen_ms;   /* k_uptime of the last good line; 0 = never */
};

/* Number of links present in the devicetree (0..INGEST_MAX_LINKS). */
int uart_ingest_link_count(void);

/* Human-readable device name of a link's UART (for logs/ACKs). */
const char *uart_ingest_link_name(int link);

/* Start RX on all links. Returns 0, or -ENODEV if a wired link is not ready. */
int uart_ingest_init(void);

/*
 * Pop the oldest queued JSON line from a link into buf (NUL-terminated,
 * "IOTC-TELEMETRY: " prefix already stripped). Returns the line length,
 * 0 when the queue is empty, or a negative errno.
 */
int uart_ingest_pop(int link, char *buf, size_t buf_size);

void uart_ingest_get_stats(int link, struct ingest_stats *out);

#ifdef __cplusplus
}
#endif

#endif /* UART_INGEST_H */
```
